AUTOSAR XML (schema 00044)
package /ComponentTypes
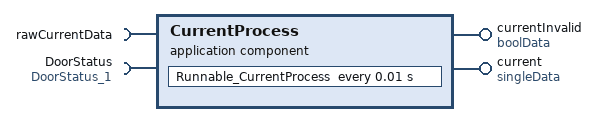
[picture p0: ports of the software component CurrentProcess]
  application sw component type CurrentProcess
    provide port currentInvalid: nonqueued-sender-com-spec=data, provided-interface=boolData
    provide port current: nonqueued-sender-com-spec=data, provided-interface=singleData
    require port rawCurrentData: nonqueued-receiver-com-spec{data-element=rawCurrentData, alive-timeout=0.3, init-value=32768}, required-interface=rawCurrentData
    require port DoorStatus: nonqueued-receiver-com-spec{data-element=DoorStatus, init-value=0}, required-interface=DoorStatus_1
    behavior CurrentProcess_InternalBehavior
      timing event TMT_Runnable_CurrentProcess: start-on-event=Runnable_CurrentProcess, period=0.01
      runnable Runnable_CurrentProcess
        data-receive-point-by-arguments:
          access REC_rawCurrentData_rawCurrentData: accessed-variable=rawCurrentData.rawCurrentData
          access REC_DoorStatus_DoorStatus: accessed-variable=DoorStatus.DoorStatus
        data-send-points:
          access SEND_current_data: accessed-variable=current.data
          access SEND_currentInvalid_data: accessed-variable=currentInvalid.data
  swc implementation CurrentProcess_Implementation: behavior=CurrentProcess_InternalBehavior
